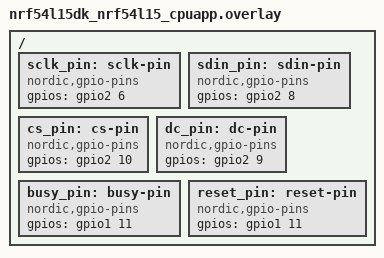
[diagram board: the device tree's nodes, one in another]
// To get started, press Ctrl+Space to bring up the completion menu and view the available nodes.

// You can also use the buttons in the sidebar to perform actions on nodes.
// Actions currently available include:

// * Enabling / disabling the node
// * Adding the bus to a bus
// * Removing the node
// * Connecting ADC channels

// For more help, browse the DeviceTree documentation at https://docs.zephyrproject.org/latest/guides/dts/index.html
// You can also visit the nRF DeviceTree extension documentation at https://docs.nordicsemi.com/bundle/nrf-connect-vscode/page/guides/ncs_configure_app.html#devicetree-support-in-the-extension

/ {
    sclk_pin: sclk-pin {
        compatible = "nordic,gpio-pins";
        gpios = <&gpio2 6 GPIO_ACTIVE_HIGH>;
        status = "okay";
    };
    sdin_pin: sdin-pin {
        compatible = "nordic,gpio-pins";
        gpios = <&gpio2 8 GPIO_ACTIVE_HIGH>;
        status = "okay";
    };
    cs_pin: cs-pin {
        compatible = "nordic,gpio-pins";
        gpios = <&gpio2 10 GPIO_ACTIVE_HIGH>;
        status = "okay";
    };
    dc_pin: dc-pin {
        compatible = "nordic,gpio-pins";
        gpios = <&gpio2 9 GPIO_ACTIVE_HIGH>;
        status = "okay";
    };
    busy_pin: busy-pin {
        compatible = "nordic,gpio-pins";
        gpios = <&gpio1 11 GPIO_ACTIVE_HIGH>;
        status = "okay";
    };
    reset_pin: reset-pin {
        compatible = "nordic,gpio-pins";
        gpios = <&gpio1 11 GPIO_ACTIVE_HIGH>;
        status = "okay";
    };
};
